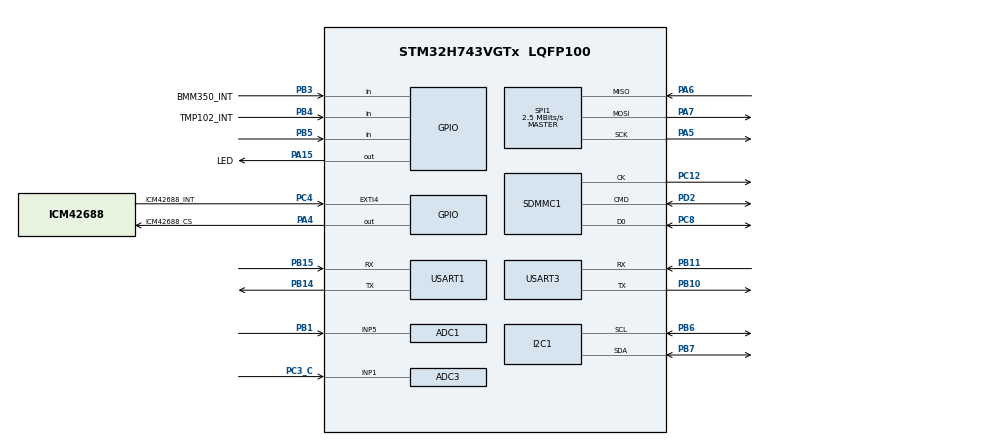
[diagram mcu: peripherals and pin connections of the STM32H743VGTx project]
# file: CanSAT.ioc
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ADC1.Channel-0\#ChannelRegularConversion=ADC_CHANNEL_5
ADC1.ContinuousConvMode=ENABLE
ADC1.NbrOfConversionFlag=1
ADC1.OffsetNumber-0\#ChannelRegularConversion=ADC_OFFSET_NONE
ADC1.OffsetSignedSaturation-0\#ChannelRegularConversion=DISABLE
ADC1.Rank-0\#ChannelRegularConversion=1
ADC1.SamplingTime-0\#ChannelRegularConversion=ADC_SAMPLETIME_1CYCLE_5
ADC1.master=1
ADC3.Channel-0\#ChannelRegularConversion=ADC_CHANNEL_1
ADC3.ContinuousConvMode=ENABLE
ADC3.NbrOfConversionFlag=1
ADC3.OffsetNumber-0\#ChannelRegularConversion=ADC_OFFSET_NONE
ADC3.OffsetSignedSaturation-0\#ChannelRegularConversion=DISABLE
ADC3.Rank-0\#ChannelRegularConversion=1
ADC3.Resolution=ADC_RESOLUTION_16B
ADC3.SamplingTime-0\#ChannelRegularConversion=ADC_SAMPLETIME_1CYCLE_5
CORTEX_M7.default_mode_Activation=1
Dma.Request0=USART1_RX
Dma.Request1=USART1_TX
Dma.Request2=USART3_RX
Dma.Request3=USART3_TX
Dma.USART1_RX.0.Direction=DMA_PERIPH_TO_MEMORY
Dma.USART1_RX.0.EventEnable=DISABLE
Dma.USART1_RX.0.FIFOMode=DMA_FIFOMODE_DISABLE
Dma.USART1_RX.0.Instance=DMA1_Stream0
Dma.USART1_RX.0.MemDataAlignment=DMA_MDATAALIGN_BYTE
Dma.USART1_RX.0.MemInc=DMA_MINC_ENABLE
Dma.USART1_RX.0.Mode=DMA_NORMAL
Dma.USART1_RX.0.PeriphDataAlignment=DMA_PDATAALIGN_BYTE
Dma.USART1_RX.0.PeriphInc=DMA_PINC_DISABLE
Dma.USART1_RX.0.Polarity=HAL_DMAMUX_REQ_GEN_RISING
Dma.USART1_RX.0.Priority=DMA_PRIORITY_VERY_HIGH
Dma.USART1_RX.0.RequestNumber=1
Dma.USART1_RX.0.SignalID=NONE
Dma.USART1_RX.0.SyncEnable=DISABLE
Dma.USART1_RX.0.SyncPolarity=HAL_DMAMUX_SYNC_NO_EVENT
Dma.USART1_RX.0.SyncRequestNumber=1
Dma.USART1_RX.0.SyncSignalID=NONE
Dma.USART1_TX.1.Direction=DMA_MEMORY_TO_PERIPH
Dma.USART1_TX.1.EventEnable=DISABLE
Dma.USART1_TX.1.FIFOMode=DMA_FIFOMODE_DISABLE
Dma.USART1_TX.1.Instance=DMA1_Stream1
Dma.USART1_TX.1.MemDataAlignment=DMA_MDATAALIGN_BYTE
Dma.USART1_TX.1.MemInc=DMA_MINC_ENABLE
Dma.USART1_TX.1.Mode=DMA_NORMAL
Dma.USART1_TX.1.PeriphDataAlignment=DMA_PDATAALIGN_BYTE
Dma.USART1_TX.1.PeriphInc=DMA_PINC_DISABLE
Dma.USART1_TX.1.Polarity=HAL_DMAMUX_REQ_GEN_RISING
Dma.USART1_TX.1.Priority=DMA_PRIORITY_VERY_HIGH
Dma.USART1_TX.1.RequestNumber=1
Dma.USART1_TX.1.SignalID=NONE
Dma.USART1_TX.1.SyncEnable=DISABLE
Dma.USART1_TX.1.SyncPolarity=HAL_DMAMUX_SYNC_NO_EVENT
Dma.USART1_TX.1.SyncRequestNumber=1
Dma.USART1_TX.1.SyncSignalID=NONE
Dma.USART3_RX.2.Direction=DMA_PERIPH_TO_MEMORY
Dma.USART3_RX.2.EventEnable=DISABLE
Dma.USART3_RX.2.FIFOMode=DMA_FIFOMODE_DISABLE
Dma.USART3_RX.2.Instance=DMA1_Stream2
Dma.USART3_RX.2.MemDataAlignment=DMA_MDATAALIGN_BYTE
Dma.USART3_RX.2.MemInc=DMA_MINC_ENABLE
Dma.USART3_RX.2.Mode=DMA_NORMAL
Dma.USART3_RX.2.PeriphDataAlignment=DMA_PDATAALIGN_BYTE
Dma.USART3_RX.2.PeriphInc=DMA_PINC_DISABLE
Dma.USART3_RX.2.Polarity=HAL_DMAMUX_REQ_GEN_RISING
Dma.USART3_RX.2.Priority=DMA_PRIORITY_VERY_HIGH
Dma.USART3_RX.2.RequestNumber=1
Dma.USART3_RX.2.SignalID=NONE
Dma.USART3_RX.2.SyncEnable=DISABLE
Dma.USART3_RX.2.SyncPolarity=HAL_DMAMUX_SYNC_NO_EVENT
Dma.USART3_RX.2.SyncRequestNumber=1
Dma.USART3_RX.2.SyncSignalID=NONE
Dma.USART3_TX.3.Direction=DMA_MEMORY_TO_PERIPH
Dma.USART3_TX.3.EventEnable=DISABLE
Dma.USART3_TX.3.FIFOMode=DMA_FIFOMODE_DISABLE
Dma.USART3_TX.3.Instance=DMA1_Stream3
Dma.USART3_TX.3.MemDataAlignment=DMA_MDATAALIGN_BYTE
Dma.USART3_TX.3.MemInc=DMA_MINC_ENABLE
Dma.USART3_TX.3.Mode=DMA_NORMAL
Dma.USART3_TX.3.PeriphDataAlignment=DMA_PDATAALIGN_BYTE
Dma.USART3_TX.3.PeriphInc=DMA_PINC_DISABLE
Dma.USART3_TX.3.Polarity=HAL_DMAMUX_REQ_GEN_RISING
Dma.USART3_TX.3.Priority=DMA_PRIORITY_VERY_HIGH
Dma.USART3_TX.3.RequestNumber=1
Dma.USART3_TX.3.SignalID=NONE
Dma.USART3_TX.3.SyncEnable=DISABLE
Dma.USART3_TX.3.SyncPolarity=HAL_DMAMUX_SYNC_NO_EVENT
Dma.USART3_TX.3.SyncRequestNumber=1
Dma.USART3_TX.3.SyncSignalID=NONE
FATFS._MAX_SS=4096
FATFS._USE_LFN=1
I2C1.Timing=0x00909BEB
Mcu.Family=STM32H7
Mcu.Name=STM32H743VGTx
Mcu.Package=LQFP100
NVIC.DMA1_Stream0_IRQn=true\:0\:0\:false\:false\:true\:false\:true\:true
NVIC.DMA1_Stream1_IRQn=true\:0\:0\:false\:false\:true\:false\:true\:true
NVIC.DMA1_Stream2_IRQn=true\:0\:0\:false\:false\:true\:false\:true\:true
NVIC.DMA1_Stream3_IRQn=true\:0\:0\:false\:false\:true\:false\:true\:true
NVIC.EXTI4_IRQn=true\:0\:0\:false\:false\:true\:true\:true\:true
NVIC.PriorityGroup=NVIC_PRIORITYGROUP_4
NVIC.USART1_IRQn=true\:0\:0\:false\:false\:true\:true\:true\:true
NVIC.USART3_IRQn=true\:0\:0\:false\:false\:true\:true\:true\:true
PA13\ (JTMS/SWDIO).Mode=Serial_Wire
PA13\ (JTMS/SWDIO).Signal=DEBUG_JTMS-SWDIO
PA14\ (JTCK/SWCLK).Mode=Serial_Wire
PA14\ (JTCK/SWCLK).Signal=DEBUG_JTCK-SWCLK
PA15\ (JTDI).GPIO_Label=LED
PA15\ (JTDI).Signal=GPIO_Output
PA4.GPIO_Label=ICM42688_CS
PA4.Signal=GPIO_Output
PA5.Mode=Full_Duplex_Master
PA5.Signal=SPI1_SCK
PA6.Mode=Full_Duplex_Master
PA6.Signal=SPI1_MISO
PA7.Mode=Full_Duplex_Master
PA7.Signal=SPI1_MOSI
PB1.Signal=ADCx_INP5
PB10.Mode=Asynchronous
PB10.Signal=USART3_TX
PB11.Mode=Asynchronous
PB11.Signal=USART3_RX
PB14.Mode=Asynchronous
PB14.Signal=USART1_TX
PB15.Mode=Asynchronous
PB15.Signal=USART1_RX
PB3\ (JTDO/TRACESWO).GPIO_Label=BMM350_INT
PB3\ (JTDO/TRACESWO).Signal=GPIO_Input
PB4\ (NJTRST).GPIO_Label=TMP102_INT
PB4\ (NJTRST).Signal=GPIO_Input
PB5.Signal=GPIO_Input
PB6.Mode=I2C
PB6.Signal=I2C1_SCL
PB7.Mode=I2C
PB7.Signal=I2C1_SDA
PC12.Mode=SD_1_bit
PC12.Signal=SDMMC1_CK
PC3_C.Mode=IN1-Single-Ended
PC3_C.Signal=ADC3_INP1
PC4.GPIO_Label=ICM42688_INT
PC4.Signal=GPXTI4
PC8.Mode=SD_1_bit
PC8.Signal=SDMMC1_D0
PD2.Mode=SD_1_bit
PD2.Signal=SDMMC1_CMD
PH0-OSC_IN\ (PH0).Mode=HSE-External-Oscillator
PH0-OSC_IN\ (PH0).Signal=RCC_OSC_IN
PH1-OSC_OUT\ (PH1).Mode=HSE-External-Oscillator
PH1-OSC_OUT\ (PH1).Signal=RCC_OSC_OUT
ProjectManager.HeapSize=0x200
ProjectManager.StackSize=0x400
ProjectManager.TargetToolchain=STM32CubeIDE
RCC.ADCFreq_Value=80000000
RCC.APB1Freq_Value=40000000
RCC.APB2Freq_Value=40000000
RCC.APB3Freq_Value=80000000
RCC.APB4Freq_Value=80000000
RCC.CortexFreq_Value=160000000
RCC.D1PPRE=RCC_APB3_DIV2
RCC.D2PPRE1=RCC_APB1_DIV4
RCC.D2PPRE2=RCC_APB2_DIV4
RCC.D3PPRE=RCC_APB4_DIV2
RCC.DIVM1=1
RCC.DIVM2=1
RCC.DIVN1=20
RCC.DIVN2=10
RCC.DIVQ1=4
RCC.HCLKFreq_Value=160000000
RCC.HSE_VALUE=16000000
RCC.PLL2FRACN=0
RCC.PLLFRACN=0
RCC.PLLSourceVirtual=RCC_PLLSOURCE_HSE
RCC.SYSCLKFreq_VALUE=160000000
RCC.SYSCLKSource=RCC_SYSCLKSOURCE_PLLCLK
RCC.USBFreq_Value=80000000
SDMMC1.ClockDiv=4
SH.ADCx_INP5.0=ADC1_INP5,IN5-Single-Ended
SPI1.BaudRatePrescaler=SPI_BAUDRATEPRESCALER_32
SPI1.CLKPhase=SPI_PHASE_2EDGE
SPI1.CLKPolarity=SPI_POLARITY_HIGH
SPI1.CalculateBaudRate=2.5 MBits/s
SPI1.DataSize=SPI_DATASIZE_8BIT
SPI1.Direction=SPI_DIRECTION_2LINES
SPI1.Mode=SPI_MODE_MASTER
SPI1.VirtualType=VM_MASTER
USART1.VirtualMode-Asynchronous=VM_ASYNC
USART3.VirtualMode-Asynchronous=VM_ASYNC
VP_FATFS_VS_SDIO.Mode=SDIO
VP_MEMORYMAP_VS_MEMORYMAP.Mode=CurAppReg
board=custom

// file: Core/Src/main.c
/* USER CODE BEGIN Header */
/**
  ******************************************************************************
  * @file           : main.c
  * @brief          : Main program body
  ******************************************************************************
  * @attention
  *
  * Copyright (c) 2025 STMicroelectronics.
  * All rights reserved.
  *
  * This software is licensed under terms that can be found in the LICENSE file
  * in the root directory of this software component.
  * If no LICENSE file comes with this software, it is provided AS-IS.
  *
  ******************************************************************************
  */
/* USER CODE END Header */
#include "main.h"
#include "fatfs.h"

/* USER CODE BEGIN Includes */
#include "altMain.hpp"
/* USER CODE END Includes */

ADC_HandleTypeDef hadc1;
ADC_HandleTypeDef hadc3;

I2C_HandleTypeDef hi2c1;

SD_HandleTypeDef hsd1;

SPI_HandleTypeDef hspi1;

UART_HandleTypeDef huart1;
UART_HandleTypeDef huart3;
DMA_HandleTypeDef hdma_usart1_rx;
DMA_HandleTypeDef hdma_usart1_tx;
DMA_HandleTypeDef hdma_usart3_rx;
DMA_HandleTypeDef hdma_usart3_tx;

void SystemClock_Config(void);
void PeriphCommonClock_Config(void);
static void MPU_Config(void);
static void MX_GPIO_Init(void);
static void MX_DMA_Init(void);
static void MX_SDMMC1_SD_Init(void);
static void MX_USART1_UART_Init(void);
static void MX_SPI1_Init(void);
static void MX_I2C1_Init(void);
static void MX_USART3_UART_Init(void);
static void MX_ADC1_Init(void);
static void MX_ADC3_Init(void);

int main(void)
{

  /* MPU Configuration--------------------------------------------------------*/
  MPU_Config();

  /* MCU Configuration--------------------------------------------------------*/

  /* Reset of all peripherals, Initializes the Flash interface and the Systick. */
  HAL_Init();

  /* Configure the system clock */
  SystemClock_Config();

  /* Configure the peripherals common clocks */
  PeriphCommonClock_Config();

  /* Initialize all configured peripherals */
  MX_GPIO_Init();
  MX_DMA_Init();
  MX_SDMMC1_SD_Init();
  MX_USART1_UART_Init();
  MX_FATFS_Init();
  MX_SPI1_Init();
  MX_I2C1_Init();
  MX_USART3_UART_Init();
  MX_ADC1_Init();
  MX_ADC3_Init();
  /* USER CODE BEGIN 2 */

  setup();

  /* USER CODE END 2 */

  /* Infinite loop */
  /* USER CODE BEGIN WHILE */
  while (1)
  {
	  loop();

    /* USER CODE END WHILE */

  }
}

void SystemClock_Config(void)
{
  RCC_OscInitTypeDef RCC_OscInitStruct = {0};
  RCC_ClkInitTypeDef RCC_ClkInitStruct = {0};

  /** Supply configuration update enable
  */
  HAL_PWREx_ConfigSupply(PWR_LDO_SUPPLY);

  /** Configure the main internal regulator output voltage
  */
  __HAL_PWR_VOLTAGESCALING_CONFIG(PWR_REGULATOR_VOLTAGE_SCALE3);

  while(!__HAL_PWR_GET_FLAG(PWR_FLAG_VOSRDY)) {}

  /** Initializes the RCC Oscillators according to the specified parameters
  * in the RCC_OscInitTypeDef structure.
  */
  RCC_OscInitStruct.OscillatorType = RCC_OSCILLATORTYPE_HSE;
  RCC_OscInitStruct.HSEState = RCC_HSE_ON;
  RCC_OscInitStruct.PLL.PLLState = RCC_PLL_ON;
  RCC_OscInitStruct.PLL.PLLSource = RCC_PLLSOURCE_HSE;
  RCC_OscInitStruct.PLL.PLLM = 1;
  RCC_OscInitStruct.PLL.PLLN = 20;
  RCC_OscInitStruct.PLL.PLLP = 2;
  RCC_OscInitStruct.PLL.PLLQ = 4;
  RCC_OscInitStruct.PLL.PLLR = 2;
  RCC_OscInitStruct.PLL.PLLRGE = RCC_PLL1VCIRANGE_3;
  RCC_OscInitStruct.PLL.PLLVCOSEL = RCC_PLL1VCOWIDE;
  RCC_OscInitStruct.PLL.PLLFRACN = 0;
  if (HAL_RCC_OscConfig(&RCC_OscInitStruct) != HAL_OK)
  {
    Error_Handler();
  }

  /** Initializes the CPU, AHB and APB buses clocks
  */
  RCC_ClkInitStruct.ClockType = RCC_CLOCKTYPE_HCLK|RCC_CLOCKTYPE_SYSCLK
                              |RCC_CLOCKTYPE_PCLK1|RCC_CLOCKTYPE_PCLK2
                              |RCC_CLOCKTYPE_D3PCLK1|RCC_CLOCKTYPE_D1PCLK1;
  RCC_ClkInitStruct.SYSCLKSource = RCC_SYSCLKSOURCE_PLLCLK;
  RCC_ClkInitStruct.SYSCLKDivider = RCC_SYSCLK_DIV1;
  RCC_ClkInitStruct.AHBCLKDivider = RCC_HCLK_DIV1;
  RCC_ClkInitStruct.APB3CLKDivider = RCC_APB3_DIV2;
  RCC_ClkInitStruct.APB1CLKDivider = RCC_APB1_DIV4;
  RCC_ClkInitStruct.APB2CLKDivider = RCC_APB2_DIV4;
  RCC_ClkInitStruct.APB4CLKDivider = RCC_APB4_DIV2;

  if (HAL_RCC_ClockConfig(&RCC_ClkInitStruct, FLASH_LATENCY_3) != HAL_OK)
  {
    Error_Handler();
  }
}

void PeriphCommonClock_Config(void)
{
  RCC_PeriphCLKInitTypeDef PeriphClkInitStruct = {0};

  /** Initializes the peripherals clock
  */
  PeriphClkInitStruct.PeriphClockSelection = RCC_PERIPHCLK_ADC;
  PeriphClkInitStruct.PLL2.PLL2M = 1;
  PeriphClkInitStruct.PLL2.PLL2N = 10;
  PeriphClkInitStruct.PLL2.PLL2P = 2;
  PeriphClkInitStruct.PLL2.PLL2Q = 2;
  PeriphClkInitStruct.PLL2.PLL2R = 2;
  PeriphClkInitStruct.PLL2.PLL2RGE = RCC_PLL2VCIRANGE_3;
  PeriphClkInitStruct.PLL2.PLL2VCOSEL = RCC_PLL2VCOMEDIUM;
  PeriphClkInitStruct.PLL2.PLL2FRACN = 0;
  PeriphClkInitStruct.AdcClockSelection = RCC_ADCCLKSOURCE_PLL2;
  if (HAL_RCCEx_PeriphCLKConfig(&PeriphClkInitStruct) != HAL_OK)
  {
    Error_Handler();
  }
}

static void MX_ADC1_Init(void)
{

  ADC_MultiModeTypeDef multimode = {0};
  ADC_ChannelConfTypeDef sConfig = {0};

  /** Common config
  */
  hadc1.Instance = ADC1;
  hadc1.Init.ClockPrescaler = ADC_CLOCK_ASYNC_DIV2;
  hadc1.Init.Resolution = ADC_RESOLUTION_16B;
  hadc1.Init.ScanConvMode = ADC_SCAN_DISABLE;
  hadc1.Init.EOCSelection = ADC_EOC_SINGLE_CONV;
  hadc1.Init.LowPowerAutoWait = DISABLE;
  hadc1.Init.ContinuousConvMode = ENABLE;
  hadc1.Init.NbrOfConversion = 1;
  hadc1.Init.DiscontinuousConvMode = DISABLE;
  hadc1.Init.ExternalTrigConv = ADC_SOFTWARE_START;
  hadc1.Init.ExternalTrigConvEdge = ADC_EXTERNALTRIGCONVEDGE_NONE;
  hadc1.Init.ConversionDataManagement = ADC_CONVERSIONDATA_DR;
  hadc1.Init.Overrun = ADC_OVR_DATA_PRESERVED;
  hadc1.Init.LeftBitShift = ADC_LEFTBITSHIFT_NONE;
  hadc1.Init.OversamplingMode = DISABLE;
  hadc1.Init.Oversampling.Ratio = 1;
  if (HAL_ADC_Init(&hadc1) != HAL_OK)
  {
    Error_Handler();
  }

  /** Configure the ADC multi-mode
  */
  multimode.Mode = ADC_MODE_INDEPENDENT;
  if (HAL_ADCEx_MultiModeConfigChannel(&hadc1, &multimode) != HAL_OK)
  {
    Error_Handler();
  }

  /** Configure Regular Channel
  */
  sConfig.Channel = ADC_CHANNEL_5;
  sConfig.Rank = ADC_REGULAR_RANK_1;
  sConfig.SamplingTime = ADC_SAMPLETIME_1CYCLE_5;
  sConfig.SingleDiff = ADC_SINGLE_ENDED;
  sConfig.OffsetNumber = ADC_OFFSET_NONE;
  sConfig.Offset = 0;
  sConfig.OffsetSignedSaturation = DISABLE;
  if (HAL_ADC_ConfigChannel(&hadc1, &sConfig) != HAL_OK)
  {
    Error_Handler();
  }

}

static void MX_ADC3_Init(void)
{

  ADC_ChannelConfTypeDef sConfig = {0};

  /** Common config
  */
  hadc3.Instance = ADC3;
  hadc3.Init.Resolution = ADC_RESOLUTION_16B;
  hadc3.Init.ScanConvMode = ADC_SCAN_DISABLE;
  hadc3.Init.EOCSelection = ADC_EOC_SINGLE_CONV;
  hadc3.Init.LowPowerAutoWait = DISABLE;
  hadc3.Init.ContinuousConvMode = ENABLE;
  hadc3.Init.NbrOfConversion = 1;
  hadc3.Init.DiscontinuousConvMode = DISABLE;
  hadc3.Init.ExternalTrigConv = ADC_SOFTWARE_START;
  hadc3.Init.ExternalTrigConvEdge = ADC_EXTERNALTRIGCONVEDGE_NONE;
  hadc3.Init.ConversionDataManagement = ADC_CONVERSIONDATA_DR;
  hadc3.Init.Overrun = ADC_OVR_DATA_PRESERVED;
  hadc3.Init.LeftBitShift = ADC_LEFTBITSHIFT_NONE;
  hadc3.Init.OversamplingMode = DISABLE;
  hadc3.Init.Oversampling.Ratio = 1;
  if (HAL_ADC_Init(&hadc3) != HAL_OK)
  {
    Error_Handler();
  }

  /** Configure Regular Channel
  */
  sConfig.Channel = ADC_CHANNEL_1;
  sConfig.Rank = ADC_REGULAR_RANK_1;
  sConfig.SamplingTime = ADC_SAMPLETIME_1CYCLE_5;
  sConfig.SingleDiff = ADC_SINGLE_ENDED;
  sConfig.OffsetNumber = ADC_OFFSET_NONE;
  sConfig.Offset = 0;
  sConfig.OffsetSignedSaturation = DISABLE;
  if (HAL_ADC_ConfigChannel(&hadc3, &sConfig) != HAL_OK)
  {
    Error_Handler();
  }

}

static void MX_I2C1_Init(void)
{

  hi2c1.Instance = I2C1;
  hi2c1.Init.Timing = 0x00909BEB;
  hi2c1.Init.OwnAddress1 = 0;
  hi2c1.Init.AddressingMode = I2C_ADDRESSINGMODE_7BIT;
  hi2c1.Init.DualAddressMode = I2C_DUALADDRESS_DISABLE;
  hi2c1.Init.OwnAddress2 = 0;
  hi2c1.Init.OwnAddress2Masks = I2C_OA2_NOMASK;
  hi2c1.Init.GeneralCallMode = I2C_GENERALCALL_DISABLE;
  hi2c1.Init.NoStretchMode = I2C_NOSTRETCH_DISABLE;
  if (HAL_I2C_Init(&hi2c1) != HAL_OK)
  {
    Error_Handler();
  }

  /** Configure Analogue filter
  */
  if (HAL_I2CEx_ConfigAnalogFilter(&hi2c1, I2C_ANALOGFILTER_ENABLE) != HAL_OK)
  {
    Error_Handler();
  }

  /** Configure Digital filter
  */
  if (HAL_I2CEx_ConfigDigitalFilter(&hi2c1, 0) != HAL_OK)
  {
    Error_Handler();
  }

}

static void MX_SDMMC1_SD_Init(void)
{

  hsd1.Instance = SDMMC1;
  hsd1.Init.ClockEdge = SDMMC_CLOCK_EDGE_RISING;
  hsd1.Init.ClockPowerSave = SDMMC_CLOCK_POWER_SAVE_DISABLE;
  hsd1.Init.BusWide = SDMMC_BUS_WIDE_1B;
  hsd1.Init.HardwareFlowControl = SDMMC_HARDWARE_FLOW_CONTROL_DISABLE;
  hsd1.Init.ClockDiv = 4;

}

static void MX_SPI1_Init(void)
{

  /* SPI1 parameter configuration*/
  hspi1.Instance = SPI1;
  hspi1.Init.Mode = SPI_MODE_MASTER;
  hspi1.Init.Direction = SPI_DIRECTION_2LINES;
  hspi1.Init.DataSize = SPI_DATASIZE_8BIT;
  hspi1.Init.CLKPolarity = SPI_POLARITY_HIGH;
  hspi1.Init.CLKPhase = SPI_PHASE_2EDGE;
  hspi1.Init.NSS = SPI_NSS_SOFT;
  hspi1.Init.BaudRatePrescaler = SPI_BAUDRATEPRESCALER_32;
  hspi1.Init.FirstBit = SPI_FIRSTBIT_MSB;
  hspi1.Init.TIMode = SPI_TIMODE_DISABLE;
  hspi1.Init.CRCCalculation = SPI_CRCCALCULATION_DISABLE;
  hspi1.Init.CRCPolynomial = 0x0;
  hspi1.Init.NSSPMode = SPI_NSS_PULSE_ENABLE;
  hspi1.Init.NSSPolarity = SPI_NSS_POLARITY_LOW;
  hspi1.Init.FifoThreshold = SPI_FIFO_THRESHOLD_01DATA;
  hspi1.Init.TxCRCInitializationPattern = SPI_CRC_INITIALIZATION_ALL_ZERO_PATTERN;
  hspi1.Init.RxCRCInitializationPattern = SPI_CRC_INITIALIZATION_ALL_ZERO_PATTERN;
  hspi1.Init.MasterSSIdleness = SPI_MASTER_SS_IDLENESS_00CYCLE;
  hspi1.Init.MasterInterDataIdleness = SPI_MASTER_INTERDATA_IDLENESS_00CYCLE;
  hspi1.Init.MasterReceiverAutoSusp = SPI_MASTER_RX_AUTOSUSP_DISABLE;
  hspi1.Init.MasterKeepIOState = SPI_MASTER_KEEP_IO_STATE_DISABLE;
  hspi1.Init.IOSwap = SPI_IO_SWAP_DISABLE;
  if (HAL_SPI_Init(&hspi1) != HAL_OK)
  {
    Error_Handler();
  }

}

static void MX_USART1_UART_Init(void)
{

  huart1.Instance = USART1;
  huart1.Init.BaudRate = 115200;
  huart1.Init.WordLength = UART_WORDLENGTH_8B;
  huart1.Init.StopBits = UART_STOPBITS_1;
  huart1.Init.Parity = UART_PARITY_NONE;
  huart1.Init.Mode = UART_MODE_TX_RX;
  huart1.Init.HwFlowCtl = UART_HWCONTROL_NONE;
  huart1.Init.OverSampling = UART_OVERSAMPLING_16;
  huart1.Init.OneBitSampling = UART_ONE_BIT_SAMPLE_DISABLE;
  huart1.Init.ClockPrescaler = UART_PRESCALER_DIV1;
  huart1.AdvancedInit.AdvFeatureInit = UART_ADVFEATURE_NO_INIT;
  if (HAL_UART_Init(&huart1) != HAL_OK)
  {
    Error_Handler();
  }
  if (HAL_UARTEx_SetTxFifoThreshold(&huart1, UART_TXFIFO_THRESHOLD_1_8) != HAL_OK)
  {
    Error_Handler();
  }
  if (HAL_UARTEx_SetRxFifoThreshold(&huart1, UART_RXFIFO_THRESHOLD_1_8) != HAL_OK)
  {
    Error_Handler();
  }
  if (HAL_UARTEx_DisableFifoMode(&huart1) != HAL_OK)
  {
    Error_Handler();
  }

}

static void MX_USART3_UART_Init(void)
{

  huart3.Instance = USART3;
  huart3.Init.BaudRate = 115200;
  huart3.Init.WordLength = UART_WORDLENGTH_8B;
  huart3.Init.StopBits = UART_STOPBITS_1;
  huart3.Init.Parity = UART_PARITY_NONE;
  huart3.Init.Mode = UART_MODE_TX_RX;
  huart3.Init.HwFlowCtl = UART_HWCONTROL_NONE;
  huart3.Init.OverSampling = UART_OVERSAMPLING_16;
  huart3.Init.OneBitSampling = UART_ONE_BIT_SAMPLE_DISABLE;
  huart3.Init.ClockPrescaler = UART_PRESCALER_DIV1;
  huart3.AdvancedInit.AdvFeatureInit = UART_ADVFEATURE_NO_INIT;
  if (HAL_UART_Init(&huart3) != HAL_OK)
  {
    Error_Handler();
  }
  if (HAL_UARTEx_SetTxFifoThreshold(&huart3, UART_TXFIFO_THRESHOLD_1_8) != HAL_OK)
  {
    Error_Handler();
  }
  if (HAL_UARTEx_SetRxFifoThreshold(&huart3, UART_RXFIFO_THRESHOLD_1_8) != HAL_OK)
  {
    Error_Handler();
  }
  if (HAL_UARTEx_DisableFifoMode(&huart3) != HAL_OK)
  {
    Error_Handler();
  }

}

static void MX_DMA_Init(void)
{

  /* DMA controller clock enable */
  __HAL_RCC_DMA1_CLK_ENABLE();

  /* DMA interrupt init */
  /* DMA1_Stream0_IRQn interrupt configuration */
  HAL_NVIC_SetPriority(DMA1_Stream0_IRQn, 0, 0);
  HAL_NVIC_EnableIRQ(DMA1_Stream0_IRQn);
  /* DMA1_Stream1_IRQn interrupt configuration */
  HAL_NVIC_SetPriority(DMA1_Stream1_IRQn, 0, 0);
  HAL_NVIC_EnableIRQ(DMA1_Stream1_IRQn);
  /* DMA1_Stream2_IRQn interrupt configuration */
  HAL_NVIC_SetPriority(DMA1_Stream2_IRQn, 0, 0);
  HAL_NVIC_EnableIRQ(DMA1_Stream2_IRQn);
  /* DMA1_Stream3_IRQn interrupt configuration */
  HAL_NVIC_SetPriority(DMA1_Stream3_IRQn, 0, 0);
  HAL_NVIC_EnableIRQ(DMA1_Stream3_IRQn);

}

static void MX_GPIO_Init(void)
{
  GPIO_InitTypeDef GPIO_InitStruct = {0};

  /* GPIO Ports Clock Enable */
  __HAL_RCC_GPIOH_CLK_ENABLE();
  __HAL_RCC_GPIOC_CLK_ENABLE();
  __HAL_RCC_GPIOA_CLK_ENABLE();
  __HAL_RCC_GPIOB_CLK_ENABLE();
  __HAL_RCC_GPIOD_CLK_ENABLE();

  /*Configure GPIO pin Output Level */
  HAL_GPIO_WritePin(GPIOA, ICM42688_CS_Pin|LED_Pin, GPIO_PIN_RESET);

  /*Configure GPIO pins : ICM42688_CS_Pin LED_Pin */
  GPIO_InitStruct.Pin = ICM42688_CS_Pin|LED_Pin;
  GPIO_InitStruct.Mode = GPIO_MODE_OUTPUT_PP;
  GPIO_InitStruct.Pull = GPIO_NOPULL;
  GPIO_InitStruct.Speed = GPIO_SPEED_FREQ_LOW;
  HAL_GPIO_Init(GPIOA, &GPIO_InitStruct);

  /*Configure GPIO pin : ICM42688_INT_Pin */
  GPIO_InitStruct.Pin = ICM42688_INT_Pin;
  GPIO_InitStruct.Mode = GPIO_MODE_IT_RISING;
  GPIO_InitStruct.Pull = GPIO_NOPULL;
  HAL_GPIO_Init(ICM42688_INT_GPIO_Port, &GPIO_InitStruct);

  /*Configure GPIO pins : BMM350_INT_Pin TMP102_INT_Pin PB5 */
  GPIO_InitStruct.Pin = BMM350_INT_Pin|TMP102_INT_Pin|GPIO_PIN_5;
  GPIO_InitStruct.Mode = GPIO_MODE_INPUT;
  GPIO_InitStruct.Pull = GPIO_NOPULL;
  HAL_GPIO_Init(GPIOB, &GPIO_InitStruct);

  /* EXTI interrupt init*/
  HAL_NVIC_SetPriority(ICM42688_INT_EXTI_IRQn, 0, 0);
  HAL_NVIC_EnableIRQ(ICM42688_INT_EXTI_IRQn);

}

 /* MPU Configuration */

void MPU_Config(void)
{
  MPU_Region_InitTypeDef MPU_InitStruct = {0};

  /* Disables the MPU */
  HAL_MPU_Disable();

  /** Initializes and configures the Region and the memory to be protected
  */
  MPU_InitStruct.Enable = MPU_REGION_ENABLE;
  MPU_InitStruct.Number = MPU_REGION_NUMBER0;
  MPU_InitStruct.BaseAddress = 0x0;
  MPU_InitStruct.Size = MPU_REGION_SIZE_4GB;
  MPU_InitStruct.SubRegionDisable = 0x87;
  MPU_InitStruct.TypeExtField = MPU_TEX_LEVEL0;
  MPU_InitStruct.AccessPermission = MPU_REGION_NO_ACCESS;
  MPU_InitStruct.DisableExec = MPU_INSTRUCTION_ACCESS_DISABLE;
  MPU_InitStruct.IsShareable = MPU_ACCESS_SHAREABLE;
  MPU_InitStruct.IsCacheable = MPU_ACCESS_NOT_CACHEABLE;
  MPU_InitStruct.IsBufferable = MPU_ACCESS_NOT_BUFFERABLE;

  HAL_MPU_ConfigRegion(&MPU_InitStruct);
  /* Enables the MPU */
  HAL_MPU_Enable(MPU_PRIVILEGED_DEFAULT);

}

void Error_Handler(void)
{
  __disable_irq();
  while (1)
  {
  }
}
